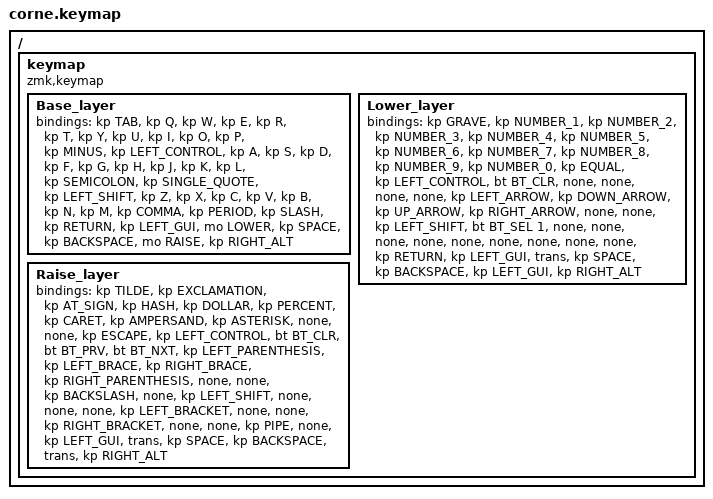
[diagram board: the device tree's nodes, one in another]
#include <behaviors.dtsi>
#include <dt-bindings/zmk/keys.h>
#include <dt-bindings/zmk/bt.h>

#define BASE 0
#define LOWER 1
#define RAISE 2

/ {
  keymap {
    compatible = "zmk,keymap";

    Base_layer {
      bindings = <
        &kp TAB &kp Q &kp W &kp E &kp R &kp T &kp Y &kp U &kp I &kp O &kp P &kp MINUS &kp LEFT_CONTROL &kp A &kp S &kp D &kp F &kp G &kp H &kp J &kp K &kp L &kp SEMICOLON &kp SINGLE_QUOTE &kp LEFT_SHIFT &kp Z &kp X &kp C &kp V &kp B &kp N &kp M &kp COMMA &kp PERIOD &kp SLASH &kp RETURN &kp LEFT_GUI &mo LOWER &kp SPACE &kp BACKSPACE &mo RAISE &kp RIGHT_ALT 
      >;
    };

    Lower_layer {
      bindings = <
        &kp GRAVE &kp NUMBER_1 &kp NUMBER_2 &kp NUMBER_3 &kp NUMBER_4 &kp NUMBER_5 &kp NUMBER_6 &kp NUMBER_7 &kp NUMBER_8 &kp NUMBER_9 &kp NUMBER_0 &kp EQUAL &kp LEFT_CONTROL &bt BT_CLR &none &none &none &none &kp LEFT_ARROW &kp DOWN_ARROW &kp UP_ARROW &kp RIGHT_ARROW &none &none &kp LEFT_SHIFT &bt BT_SEL 1 &none &none &none &none &none &none &none &none &none &kp RETURN &kp LEFT_GUI &trans &kp SPACE &kp BACKSPACE &kp LEFT_GUI &kp RIGHT_ALT 
      >;
    };

    Raise_layer {
      bindings = <
        &kp TILDE &kp EXCLAMATION &kp AT_SIGN &kp HASH &kp DOLLAR &kp PERCENT &kp CARET &kp AMPERSAND &kp ASTERISK &none &none &kp ESCAPE &kp LEFT_CONTROL &bt BT_CLR &bt BT_PRV &bt BT_NXT &kp LEFT_PARENTHESIS &kp LEFT_BRACE &kp RIGHT_BRACE &kp RIGHT_PARENTHESIS &none &none &kp BACKSLASH &none &kp LEFT_SHIFT &none &none &none &kp LEFT_BRACKET &none &none &kp RIGHT_BRACKET &none &none &kp PIPE &none &kp LEFT_GUI &trans &kp SPACE &kp BACKSPACE &trans &kp RIGHT_ALT 
      >;
    };

  };
};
